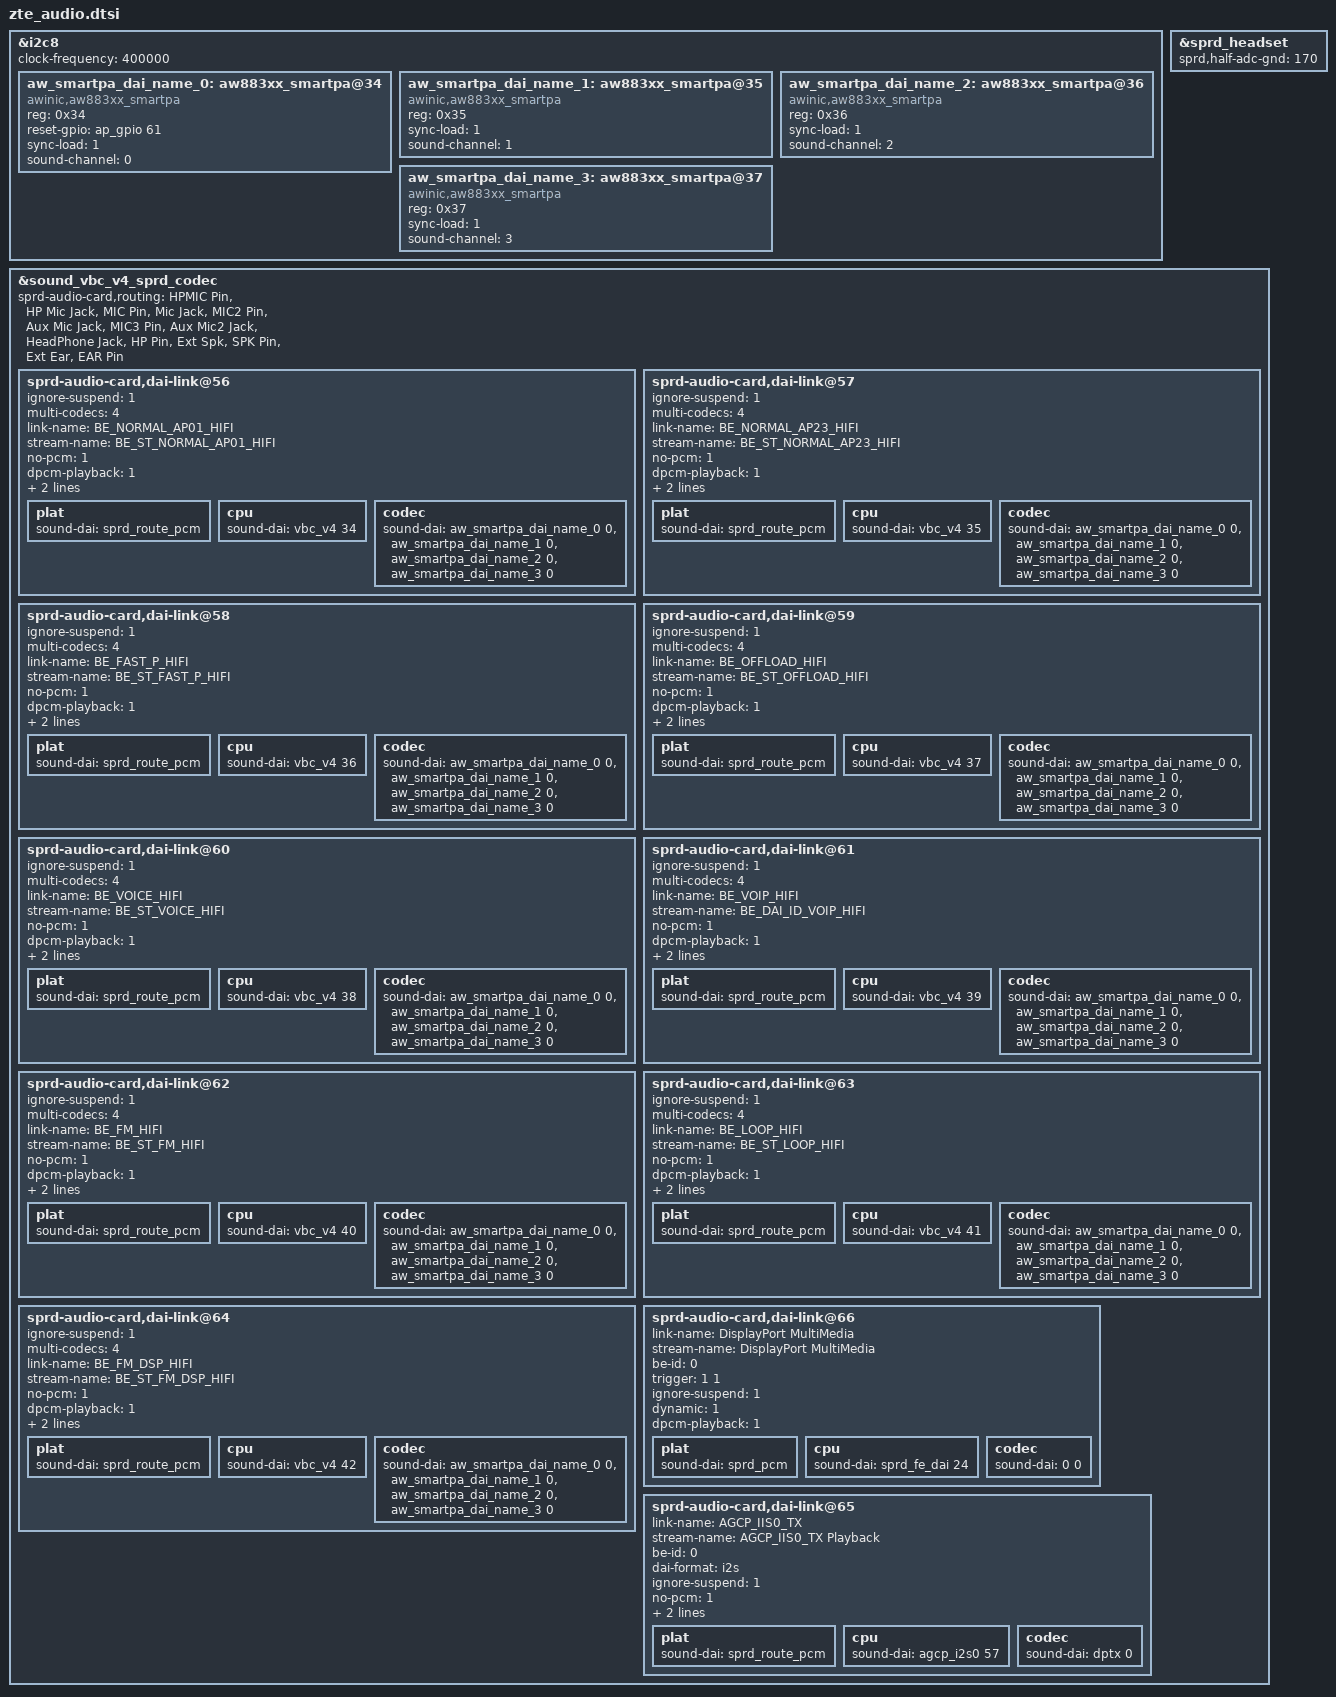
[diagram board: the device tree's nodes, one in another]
&i2c8 {
	status = "okay";
	clock-frequency = <400000>;
	#address-cells = <1>;
	#size-cells = <0>;

	aw_smartpa_dai_name_0: aw883xx_smartpa@34 {
		status = "okay";
		compatible = "awinic,aw883xx_smartpa";
		#sound-dai-cells = <1>;
		reg = <0x34>;
		reset-gpio = <&ap_gpio 61 GPIO_ACTIVE_HIGH>;
		sync-load = <1>;
		sound-channel = <0>;
	};
	aw_smartpa_dai_name_1: aw883xx_smartpa@35 {
		status = "okay";
		compatible = "awinic,aw883xx_smartpa";
		#sound-dai-cells = <1>;
		reg = <0x35>;
		sync-load = <1>;
		sound-channel = <1>;
	};
	aw_smartpa_dai_name_2: aw883xx_smartpa@36 {
		status = "okay";
		compatible = "awinic,aw883xx_smartpa";
		#sound-dai-cells = <1>;
		reg = <0x36>;
		sync-load = <1>;
		sound-channel = <2>;
	};
	aw_smartpa_dai_name_3: aw883xx_smartpa@37 {
		status = "okay";
		compatible = "awinic,aw883xx_smartpa";
		#sound-dai-cells = <1>;
		reg = <0x37>;
		sync-load = <1>;
		sound-channel = <3>;
	};
};

&sprd_headset {
	status = "okay";
	sprd,half-adc-gnd = <170>;
};

&sound_vbc_v4_sprd_codec {
	status = "okay";
	sprd-audio-card,routing =
		"HPMIC Pin", "HP Mic Jack",
		"MIC Pin", "Mic Jack",
		"MIC2 Pin", "Aux Mic Jack",
		"MIC3 Pin", "Aux Mic2 Jack",
		"HeadPhone Jack", "HP Pin",
		"Ext Spk", "SPK Pin",
		"Ext Ear", "EAR Pin";

	/* 38: akm hifi normal ap01 */
	sprd-audio-card,dai-link@56 {
		ignore-suspend = <1>;
		multi-codecs = <4>;
		link-name = "BE_NORMAL_AP01_HIFI";
		stream-name = "BE_ST_NORMAL_AP01_HIFI";
		no-pcm = <1>;
		dpcm-playback = <1>;
		be-id = <0>;
		dai-format = "i2s";
		plat {
			sound-dai = <&sprd_route_pcm>;
		};
		cpu {
			sound-dai = <&vbc_v4 34>;
		};
		codec {
			sound-dai = <&aw_smartpa_dai_name_0 0>,<&aw_smartpa_dai_name_1 0>,<&aw_smartpa_dai_name_2 0>,<&aw_smartpa_dai_name_3 0>;
		};
	};

	/* 39: akm hifi normal ap23 */
	sprd-audio-card,dai-link@57 {
		ignore-suspend = <1>;
		multi-codecs = <4>;
		link-name = "BE_NORMAL_AP23_HIFI";
		stream-name = "BE_ST_NORMAL_AP23_HIFI";
		no-pcm = <1>;
		dpcm-playback = <1>;
		be-id = <0>;
		dai-format = "i2s";
		plat {
			sound-dai = <&sprd_route_pcm>;
		};
		cpu {
			sound-dai = <&vbc_v4 35>;
		};
		codec {
			sound-dai = <&aw_smartpa_dai_name_0 0>,<&aw_smartpa_dai_name_1 0>,<&aw_smartpa_dai_name_2 0>,<&aw_smartpa_dai_name_3 0>;
		};
	};

	/* 40: akm hifi fast playback */
	sprd-audio-card,dai-link@58 {
		ignore-suspend = <1>;
		multi-codecs = <4>;
		link-name = "BE_FAST_P_HIFI";
		stream-name = "BE_ST_FAST_P_HIFI";
		no-pcm = <1>;
		dpcm-playback = <1>;
		be-id = <0>;
		dai-format = "i2s";
		plat {
			sound-dai = <&sprd_route_pcm>;
		};
		cpu {
			sound-dai = <&vbc_v4 36>;
		};
		codec {
			sound-dai = <&aw_smartpa_dai_name_0 0>,<&aw_smartpa_dai_name_1 0>,<&aw_smartpa_dai_name_2 0>,<&aw_smartpa_dai_name_3 0>;
		};
	};

	/* 41: akm hifi offload */
	sprd-audio-card,dai-link@59 {
		ignore-suspend = <1>;
		multi-codecs = <4>;
		link-name = "BE_OFFLOAD_HIFI";
		stream-name = "BE_ST_OFFLOAD_HIFI";
		no-pcm = <1>;
		dpcm-playback = <1>;
		be-id = <0>;
		dai-format = "i2s";
		plat {
			sound-dai = <&sprd_route_pcm>;
		};
		cpu {
			sound-dai = <&vbc_v4 37>;
		};
		codec {
			sound-dai = <&aw_smartpa_dai_name_0 0>,<&aw_smartpa_dai_name_1 0>,<&aw_smartpa_dai_name_2 0>,<&aw_smartpa_dai_name_3 0>;
		};
	};

	/* 42: akm hifi voice */
	sprd-audio-card,dai-link@60 {
		ignore-suspend = <1>;
		multi-codecs = <4>;
		link-name = "BE_VOICE_HIFI";
		stream-name = "BE_ST_VOICE_HIFI";
		no-pcm = <1>;
		dpcm-playback = <1>;
		be-id = <0>;
		dai-format = "i2s";
		plat {
			sound-dai = <&sprd_route_pcm>;
		};
		cpu {
			sound-dai = <&vbc_v4 38>;
		};
		codec {
			sound-dai = <&aw_smartpa_dai_name_0 0>,<&aw_smartpa_dai_name_1 0>,<&aw_smartpa_dai_name_2 0>,<&aw_smartpa_dai_name_3 0>;
		};
	};

	/* 43: akm hifi voip */
	sprd-audio-card,dai-link@61 {
		ignore-suspend = <1>;
		multi-codecs = <4>;
		link-name = "BE_VOIP_HIFI";
		stream-name = "BE_DAI_ID_VOIP_HIFI";
		no-pcm = <1>;
		dpcm-playback = <1>;
		be-id = <0>;
		dai-format = "i2s";
		plat {
			sound-dai = <&sprd_route_pcm>;
		};
		cpu {
			sound-dai = <&vbc_v4 39>;
		};
		codec {
			sound-dai = <&aw_smartpa_dai_name_0 0>,<&aw_smartpa_dai_name_1 0>,<&aw_smartpa_dai_name_2 0>,<&aw_smartpa_dai_name_3 0>;
		};
	};

	/* 44: akm hifi fm */
	sprd-audio-card,dai-link@62 {
		ignore-suspend = <1>;
		multi-codecs = <4>;
		link-name = "BE_FM_HIFI";
		stream-name = "BE_ST_FM_HIFI";
		no-pcm = <1>;
		dpcm-playback = <1>;
		be-id = <0>;
		dai-format = "i2s";
		plat {
			sound-dai = <&sprd_route_pcm>;
		};
		cpu {
			sound-dai = <&vbc_v4 40>;
		};
		codec {
			sound-dai = <&aw_smartpa_dai_name_0 0>,<&aw_smartpa_dai_name_1 0>,<&aw_smartpa_dai_name_2 0>,<&aw_smartpa_dai_name_3 0>;
		};
	};

	/* 45: akm hifi loopback */
	sprd-audio-card,dai-link@63 {
		ignore-suspend = <1>;
		multi-codecs = <4>;
		link-name = "BE_LOOP_HIFI";
		stream-name = "BE_ST_LOOP_HIFI";
		no-pcm = <1>;
		dpcm-playback = <1>;
		be-id = <0>;
		dai-format = "i2s";
		plat {
			sound-dai = <&sprd_route_pcm>;
		};
		cpu {
			sound-dai = <&vbc_v4 41>;
		};
		codec {
			sound-dai = <&aw_smartpa_dai_name_0 0>,<&aw_smartpa_dai_name_1 0>,<&aw_smartpa_dai_name_2 0>,<&aw_smartpa_dai_name_3 0>;
		};
	};

	/* 46: akm hifi fm dsp */
	sprd-audio-card,dai-link@64 {
		ignore-suspend = <1>;
		multi-codecs = <4>;
		link-name = "BE_FM_DSP_HIFI";
		stream-name = "BE_ST_FM_DSP_HIFI";
		no-pcm = <1>;
		dpcm-playback = <1>;
		be-id = <0>;
		dai-format = "i2s";
		plat {
			sound-dai = <&sprd_route_pcm>;
		};
		cpu {
			sound-dai = <&vbc_v4 42>;
		};
		codec {
			sound-dai = <&aw_smartpa_dai_name_0 0>,<&aw_smartpa_dai_name_1 0>,<&aw_smartpa_dai_name_2 0>,<&aw_smartpa_dai_name_3 0>;
		};
	};

	/* 24: fe DisplayPort pcm */
	sprd-audio-card,dai-link@66 {
		link-name = "DisplayPort MultiMedia";
		stream-name = "DisplayPort MultiMedia";
		be-id = <0>;
		trigger = <1 1>;
		ignore-suspend = <1>;
		dynamic = <1>;
		dpcm-playback = <1>;
		plat {
			sound-dai = <&sprd_pcm>;
		};
		cpu {
			sound-dai = <&sprd_fe_dai 24>;
		};
		codec {
			sound-dai = <0 0>;
		};
	};

	/* agcp_i2s0: be dp pcm */
	sprd-audio-card,dai-link@65 {
		link-name = "AGCP_IIS0_TX";
		stream-name = "AGCP_IIS0_TX Playback";
		be-id = <0>;
		dai-format = "i2s";
		ignore-suspend = <1>;
		no-pcm = <1>;
		dpcm-playback = <1>;
		ignore-pmdown-time = <1>;
		plat {
			sound-dai = <&sprd_route_pcm>;
		};
		cpu {
			sound-dai = <&agcp_i2s0 57>;
		};
		codec {
			sound-dai = <&dptx 0>;
		};
	};
};


